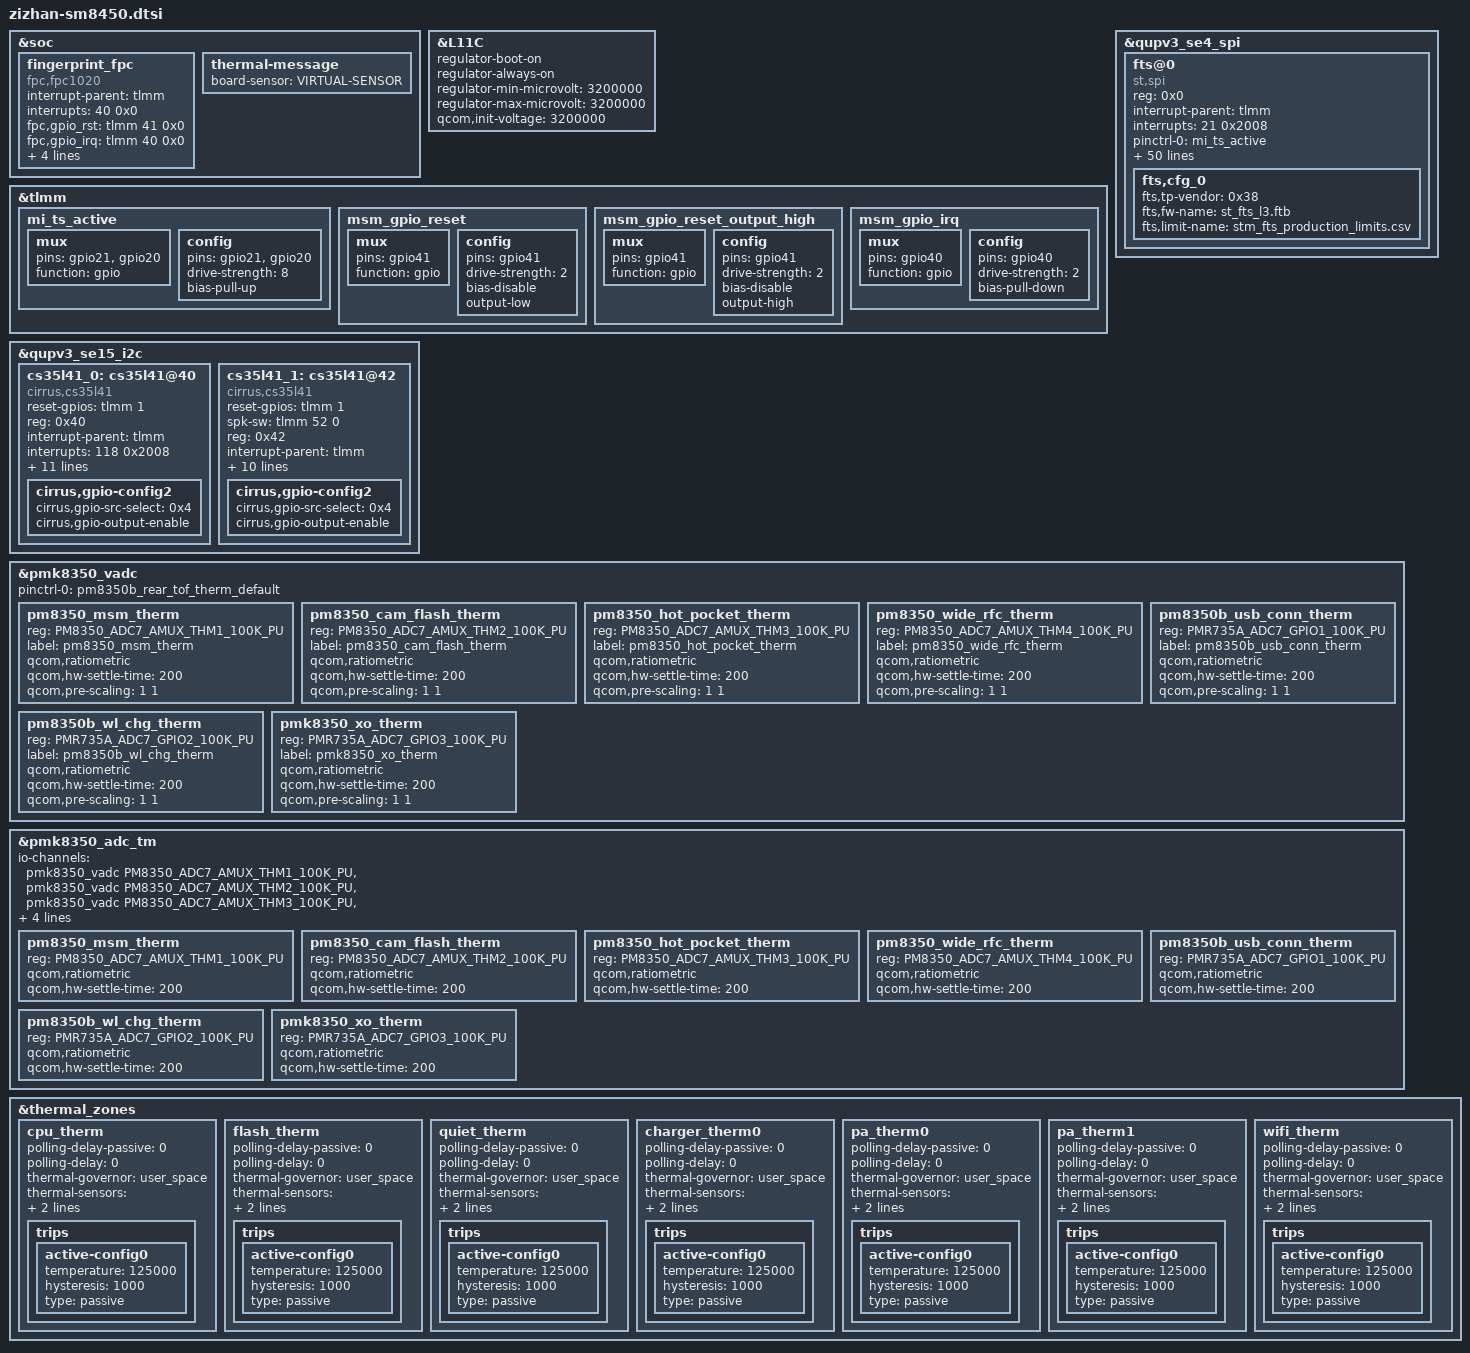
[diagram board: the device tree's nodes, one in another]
/*
   this file is for attribution only of zizhan
   And public attribution of xiaomi platforms
*/
#include "zizhan-pinctrl.dtsi"
#include "xiaomi-sm8450-common.dtsi"
&soc {
	fingerprint_fpc {
		status = "ok";
		compatible = "fpc,fpc1020";
		interrupt-parent = <&tlmm>;
		interrupts = <40 0x0>;
		fpc,gpio_rst    = <&tlmm 41 0x0>;
		fpc,gpio_irq    = <&tlmm 40 0x0>;
		fp_vdd_vreg-supply = <&L11C>;
		pinctrl-names = "fpc1020_reset_reset",
                                "fpc1020_reset_active",
                                "fpc1020_irq_active";

		pinctrl-0 = <&msm_gpio_reset>;
		pinctrl-1 = <&msm_gpio_reset_output_high>;
		pinctrl-2 = <&msm_gpio_irq>;
	};
};
&L11C {
	regulator-boot-on;
	regulator-always-on;
	regulator-min-microvolt = <3200000>;
	regulator-max-microvolt = <3200000>;
	qcom,init-voltage = <3200000>;
};
&tlmm {
	mi_ts_active: mi_ts_active {
		mux {
				pins = "gpio21", "gpio20";
				function = "gpio";
		};

		config {
				pins = "gpio21", "gpio20";
				drive-strength = <8>;
				bias-pull-up;
		};
	};

	/* FP_RESET_N */
	msm_gpio_reset: msm_gpio_reset {
		mux {
			pins = "gpio41";
			function = "gpio";
		};
		config {
			pins = "gpio41";
			drive-strength = <2>;
			bias-disable;
			output-low;
		};
	};

        /* FP_RESET_N, state device active*/
	msm_gpio_reset_output_high: msm_gpio_reset_output_high {
		mux {
			pins = "gpio41";
			function = "gpio";
		};
		config {
			pins = "gpio41";
			drive-strength = <2>;
			bias-disable;
			output-high;
		};
	};
        /* FP_INT_N */
	msm_gpio_irq: msm_gpio_irq {
		mux {
			pins = "gpio40";
			function = "gpio";
		};
		config {
			pins = "gpio40";
			drive-strength = <2>;
			bias-pull-down;
		};
	};
};

&qupv3_se4_spi {
	status = "ok";
	fts@0 {
		status = "ok";
		compatible = "st,spi";
		reg = <0x0>;
		interrupt-parent = <&tlmm>;
		interrupts = <21 0x2008>;
		pinctrl-names = "pmx_ts_active", "pmx_ts_suspend";
		pinctrl-0 = <&mi_ts_active>;
		pinctrl-1 = <&ts_int_suspend &ts_reset_suspend>;
		avdd-supply = <&L7C>;
		vdd-supply = <&L2C>;
		/*panel = <&dsi_k8_42_02_0a_dsc_cmd>;*/
		fts,pwr-reg-name = "avdd";
		fts,bus-reg-name = "vdd";
		fts,irq-gpio = <&tlmm 21 0x2008>;
		fts,irq-gpio-name = "fts_irq";
		fts,reset-gpio-enable;
		fts,reset-gpio = <&tlmm 20 0x00>;
		fts,reset-gpio-name = "fts_rst";
		fts,irq-flags = <0x2008>;
		fts,x-max = <1080>;
		fts,y-max = <2400>;
		fts,fod-lx = <433>;
		fts,fod-ly = <2056>;
		fts,fod-x-size = <214>;
		fts,fod-y-size = <214>;
		fts,support-fod;
		spi-max-frequency = <12000000>;
		fts,default-fw-name = "st_fts_l3.ftb";
		fts,htp-fw-name = "st_fts_l3_thp.ftb";
		fts,config-array-size = <1>;
		fts,touch-follow-performance-def = <3>;
		fts,touch-tap-sensitivity-def = <4>;
		fts,touch-aim-sensitivity-def = <3>;
		fts,touch-tap-stability-def = <3>;
		fts,cornerfilter-area-step1 = <150>;
		fts,cornerfilter-area-step2 = <280>;
		fts,cornerfilter-area-step3 = <400>;
		fts,touch-deadzone-filter-ver = <2 0 0 0 0 0 0 0
										2 1 0 0 0 0 0 0
										2 2 0 0 0 3199 0 0
										2 3 1439 0 1439 3199 0 0>;
		fts,touch-deadzone-filter-hor = <2 0 0 0 1439 7 0 0
										2 1 0 3192 1439 3199 0 0
										2 2 0 0 0 3199 0 0
										2 3 1439 0 1439 3199 0 0>;
		fts,touch-edgezone-filter-ver = <1 0 0 0 0 0 0 0
										1 1 0 0 0 0 0 0
										1 2 0 0 60 3199 0 0
										1 3 1379 0 1439 3199 0 0>;
		fts,touch-edgezone-filter-hor = <1 0 0 0 1439 70 0 0
										1 1 0 3129 1439 3199 0 0
										1 2 0 0 60 3199 0 0
										1 3 1379 0 1439 3199 0 0>;
		fts,touch-cornerzone-filter-ver = <0 0 0 0 0 0 0 0
										0 1 0 0 0 0 0 0
										0 2 0 2799 250 3199 0 0
										0 3 1189 2799 1439 3199 0 0>;
		fts,touch-cornerzone-filter-hor1 = <0 0 0 0 280 280 0 0
										0 1 0 0 0 0 0 0
										0 2 0 2919 280 3199 0 0
										0 3 0 0 0 0 0 0>;
		fts,touch-cornerzone-filter-hor2 = <0 0 0 0 0 0 0 0
										0 1 1159 0 1439 280 0 0
										0 2 0 0 0 0 0 0
										0 3 1159 2919 1439 3199 0 0>;
		fts,touch-follow-performance = <10 15 1
										8 15 1
										6 15 1
										4 15 1
										2 15 1>;
		fts,touch-tap-sensitivity = <160 150 140 120 100>;
		fts,touch-aim-sensitivity = <10 8 6 4 2>;
		fts,touch-tap-stability = <8 12 15 18 25>;
		fts,touch-expert-array = <6 15 1 120 6 15
								  2 15 1 120 4 15
								  4 15 1 120 2 15>;
		fts,cfg_0 {
			fts,tp-vendor = <0x38>;
			fts,fw-name = "st_fts_l3.ftb";
			fts,limit-name = "stm_fts_production_limits.csv";
		};
	};
};

&qupv3_se15_i2c {
	status = "ok";
	cs35l41_0: cs35l41@40 {
		status = "ok";
		compatible = "cirrus,cs35l41";
		reset-gpios = <&tlmm 1 0>;
		reg = <0x40>;
		interrupt-parent = <&tlmm>;
		interrupts = <118 0x2008>;
		pinctrl-names = "default";
		pinctrl-0 = <&cirrus_reset_default_0 &cirrus_irq_default_0>;
		cirrus,temp-warn_threshold = <3>;
		cirrus,boost-peak-milliamp = <4000>;
		cirrus,boost-ind-nanohenry = <1000>;
		cirrus,boost-cap-microfarad = <15>;
		cirrus,asp-sdout-hiz = <3>;
		cirrus,right-channel-amp;
		sound-name-prefix = "B";
		cirrus,fast-switch = "B-music.txt", "B-handfree.txt";
		cirrus,gpio-config2 {
			cirrus,gpio-src-select = <0x4>;
			cirrus,gpio-output-enable;
		};
	};
	cs35l41_1: cs35l41@42 {
		status = "ok";
		compatible = "cirrus,cs35l41";
		reset-gpios = <&tlmm 1 0>;
		spk-sw = <&tlmm 52 0>;
		reg = <0x42>;
		interrupt-parent = <&tlmm>;
		interrupts = <63 0x2008>;
		pinctrl-names = "default";
		pinctrl-0 = <&cirrus_irq_default_1>;
		cirrus,temp-warn_threshold = <3>;
		cirrus,boost-peak-milliamp = <4000>;
		cirrus,boost-ind-nanohenry = <1000>;
		cirrus,boost-cap-microfarad = <15>;
		cirrus,asp-sdout-hiz = <3>;
		sound-name-prefix = "T";
		cirrus,fast-switch = "T-music.txt", "T-handset.txt", "T-handfree.txt";
		cirrus,gpio-config2 {
			cirrus,gpio-src-select = <0x4>;
			cirrus,gpio-output-enable;
		};
	};
};

&pmk8350_vadc {
	pinctrl-names = "default";
	pinctrl-0 = <&pm8350b_rear_tof_therm_default>;

	pm8350_msm_therm {
		reg = <PM8350_ADC7_AMUX_THM1_100K_PU>;
		label = "pm8350_msm_therm";
		qcom,ratiometric;
		qcom,hw-settle-time = <200>;
		qcom,pre-scaling = <1 1>;
	};

	pm8350_cam_flash_therm {
		reg = <PM8350_ADC7_AMUX_THM2_100K_PU>;
		label = "pm8350_cam_flash_therm";
		qcom,ratiometric;
		qcom,hw-settle-time = <200>;
		qcom,pre-scaling = <1 1>;
	};

	pm8350_hot_pocket_therm {
		reg = <PM8350_ADC7_AMUX_THM3_100K_PU>;
		label = "pm8350_hot_pocket_therm";
		qcom,ratiometric;
		qcom,hw-settle-time = <200>;
		qcom,pre-scaling = <1 1>;
	};

	pm8350_wide_rfc_therm {
		reg = <PM8350_ADC7_AMUX_THM4_100K_PU>;
		label = "pm8350_wide_rfc_therm";
		qcom,ratiometric;
		qcom,hw-settle-time = <200>;
		qcom,pre-scaling = <1 1>;
	};

	pm8350b_usb_conn_therm {
		reg = <PMR735A_ADC7_GPIO1_100K_PU>;
		label = "pm8350b_usb_conn_therm";
		qcom,ratiometric;
		qcom,hw-settle-time = <200>;
		qcom,pre-scaling = <1 1>;
	};

	pm8350b_wl_chg_therm {
		reg = <PMR735A_ADC7_GPIO2_100K_PU>;
		label = "pm8350b_wl_chg_therm";
		qcom,ratiometric;
		qcom,hw-settle-time = <200>;
		qcom,pre-scaling = <1 1>;
	};

	pmk8350_xo_therm {
		reg = <PMR735A_ADC7_GPIO3_100K_PU>;
		label = "pmk8350_xo_therm";
		qcom,ratiometric;
		qcom,hw-settle-time = <200>;
		qcom,pre-scaling = <1 1>;
	};
};

&pmk8350_adc_tm {
	io-channels = <&pmk8350_vadc PM8350_ADC7_AMUX_THM1_100K_PU>,
			<&pmk8350_vadc PM8350_ADC7_AMUX_THM2_100K_PU>,
			<&pmk8350_vadc PM8350_ADC7_AMUX_THM3_100K_PU>,
			<&pmk8350_vadc PM8350_ADC7_AMUX_THM4_100K_PU>,
			<&pmk8350_vadc PMR735A_ADC7_GPIO1_100K_PU>,
			<&pmk8350_vadc PMR735A_ADC7_GPIO2_100K_PU>,
			<&pmk8350_vadc PMR735A_ADC7_GPIO3_100K_PU>;

	pm8350_msm_therm {
		reg = <PM8350_ADC7_AMUX_THM1_100K_PU>;
		qcom,ratiometric;
		qcom,hw-settle-time = <200>;
	};

	pm8350_cam_flash_therm {
		reg = <PM8350_ADC7_AMUX_THM2_100K_PU>;
		qcom,ratiometric;
		qcom,hw-settle-time = <200>;
	};

	pm8350_hot_pocket_therm {
		reg = <PM8350_ADC7_AMUX_THM3_100K_PU>;
		qcom,ratiometric;
		qcom,hw-settle-time = <200>;
	};

	pm8350_wide_rfc_therm {
		reg = <PM8350_ADC7_AMUX_THM4_100K_PU>;
		qcom,ratiometric;
		qcom,hw-settle-time = <200>;
	};

	pm8350b_usb_conn_therm {
		reg = <PMR735A_ADC7_GPIO1_100K_PU>;
		qcom,ratiometric;
		qcom,hw-settle-time = <200>;
	};

	pm8350b_wl_chg_therm {
		reg = <PMR735A_ADC7_GPIO2_100K_PU>;
		qcom,ratiometric;
		qcom,hw-settle-time = <200>;
	};

	pmk8350_xo_therm {
		reg = <PMR735A_ADC7_GPIO3_100K_PU>;
		qcom,ratiometric;
		qcom,hw-settle-time = <200>;
	};
};

&thermal_zones {
	cpu_therm {
		polling-delay-passive = <0>;
		polling-delay = <0>;
		thermal-governor = "user_space";
		thermal-sensors = <&pmk8350_adc_tm PM8350_ADC7_AMUX_THM1_100K_PU>;
		wake-capable-sensor;
		trips {
			active-config0 {
				temperature = <125000>;
				hysteresis = <1000>;
				type = "passive";
			};
		};
	};

	flash_therm {
		polling-delay-passive = <0>;
		polling-delay = <0>;
		thermal-governor = "user_space";
		thermal-sensors = <&pmk8350_adc_tm PM8350_ADC7_AMUX_THM2_100K_PU>;
		wake-capable-sensor;
		trips {
			active-config0 {
				temperature = <125000>;
				hysteresis = <1000>;
				type = "passive";
			};
		};
	};

	quiet_therm {
		polling-delay-passive = <0>;
		polling-delay = <0>;
		thermal-governor = "user_space";
		thermal-sensors = <&pmk8350_adc_tm PM8350_ADC7_AMUX_THM3_100K_PU>;
		wake-capable-sensor;
		trips {
			active-config0 {
				temperature = <125000>;
				hysteresis = <1000>;
				type = "passive";
			};
		};
	};

	charger_therm0 {
		polling-delay-passive = <0>;
		polling-delay = <0>;
		thermal-governor = "user_space";
		thermal-sensors = <&pmk8350_adc_tm PM8350_ADC7_AMUX_THM4_100K_PU>;
		wake-capable-sensor;
		trips {
			active-config0 {
				temperature = <125000>;
				hysteresis = <1000>;
				type = "passive";
			};
		};
	};

	pa_therm0 {
		polling-delay-passive = <0>;
		polling-delay = <0>;
		thermal-governor = "user_space";
		thermal-sensors = <&pmk8350_adc_tm PMR735A_ADC7_GPIO1_100K_PU>;
		wake-capable-sensor;
		trips {
			active-config0 {
				temperature = <125000>;
				hysteresis = <1000>;
				type = "passive";
			};
		};
	};

	pa_therm1 {
		polling-delay-passive = <0>;
		polling-delay = <0>;
		thermal-governor = "user_space";
		thermal-sensors = <&pmk8350_adc_tm PMR735A_ADC7_GPIO2_100K_PU>;
		wake-capable-sensor;
		trips {
			active-config0 {
				temperature = <125000>;
				hysteresis = <1000>;
				type = "passive";
			};
		};
	};

	wifi_therm {
		polling-delay-passive = <0>;
		polling-delay = <0>;
		thermal-governor = "user_space";
		thermal-sensors = <&pmk8350_adc_tm PMR735A_ADC7_GPIO3_100K_PU>;
		wake-capable-sensor;
		trips {
			active-config0 {
				temperature = <125000>;
				hysteresis = <1000>;
				type = "passive";
			};
		};
	};
};

&soc {
	thermal-message {
		board-sensor = "VIRTUAL-SENSOR";
	};
};
